# VPAC0_PAR_VPAC_LDC0_S_VBUSP_PIXWRINTF_DUALC_LUTCFG_DUALC_LUT register map
Vendor: Texas Instruments
Peripheral module from a debugger description file (folder J721S2).
Registers are 32-bit, read-write, reset 0x0 unless marked. A register's access mark holds for its fields unless they carry their own. Offsets are as the file gives them; lines under a group give offsets from that group; [hi:lo] are bit positions; {n}, {i} and the like mark numbered series; 'fields as' and 'values as' point back to an identical list; <NAME> marks a mode.

## VPAC0_PAR_VPAC_LDC0_S_VBUSP_PIXWRINTF_DUALC_LUTCFG_DUALC_LUT
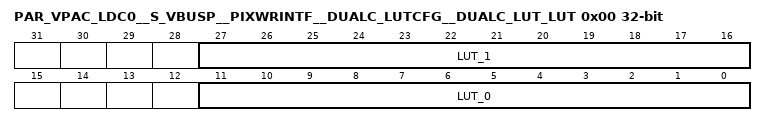
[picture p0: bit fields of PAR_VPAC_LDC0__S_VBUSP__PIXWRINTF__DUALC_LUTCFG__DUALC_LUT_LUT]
0x00 PAR_VPAC_LDC0__S_VBUSP__PIXWRINTF__DUALC_LUTCFG__DUALC_LUT_LUT — dualc width conversion LUT
  [27:16] LUT_1 — Bank-1
  [11:0] LUT_0 — Bank-0
